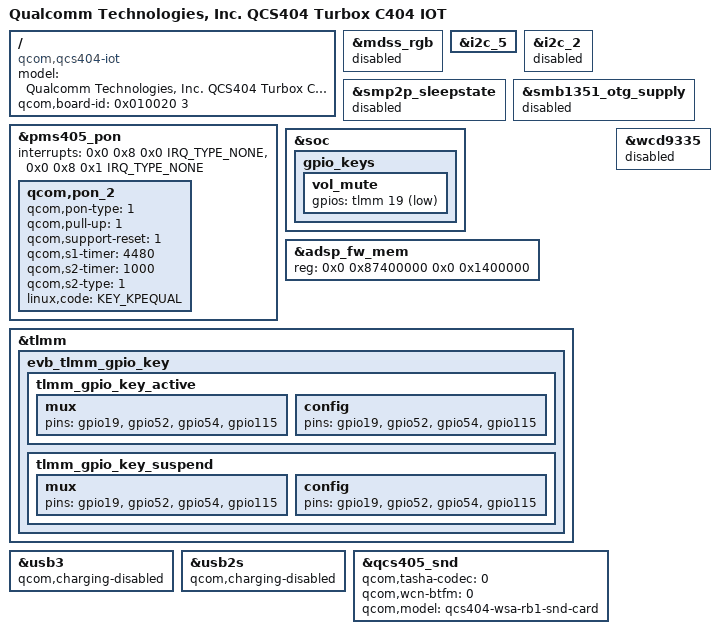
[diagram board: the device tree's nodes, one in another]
/*
 * Copyright (c) 2019-2020, The Linux Foundation. All rights reserved.
 *
 * This program is free software; you can redistribute it and/or modify
 * it under the terms of the GNU General Public License version 2 and
 * only version 2 as published by the Free Software Foundation.
 *
 * This program is distributed in the hope that it will be useful,
 * but WITHOUT ANY WARRANTY; without even the implied warranty of
 * MERCHANTABILITY or FITNESS FOR A PARTICULAR PURPOSE.  See the
 * GNU General Public License for more details.
 */

/dts-v1/;

#include "qcs404.dtsi"
#include "qcs405-wsa-audio-overlay.dtsi"

/ {
	model = "Qualcomm Technologies, Inc. QCS404 Turbox C404 IOT";
	compatible = "qcom,qcs404-iot", "qcom,qcs404", "qcom,iot";
	qcom,board-id = <0x010020 3>;
};

&mdss_rgb {
	status = "disabled";
};

&i2c_5 {
	status = "ok";
};

&i2c_2 {
	status = "disabled";
};

&smp2p_sleepstate {
	status = "disabled";
};

&smb1351_otg_supply {
	status = "disabled";
};

&pms405_pon {
	interrupts = <0x0 0x8 0x0 IRQ_TYPE_NONE>,
		     <0x0 0x8 0x1 IRQ_TYPE_NONE>;
	interrupt-names = "kpdpwr", "resin";
	qcom,pon_2 {
		qcom,pon-type = <1>;
		qcom,pull-up = <1>;
		qcom,support-reset = <1>;
		qcom,s1-timer = <4480>;
		qcom,s2-timer = <1000>;
		qcom,s2-type = <1>;
		linux,code = <KEY_KPEQUAL>;
	};
};

&soc {
	gpio_keys {
		vol_mute {
			gpios = <&tlmm 19 GPIO_ACTIVE_LOW>;
		};
	};
};

&adsp_fw_mem {
	reg = <0x0 0x87400000 0x0 0x1400000>;
};

&tlmm {
	evb_tlmm_gpio_key{
		tlmm_gpio_key_active: tlmm_gpio_key_active {
			mux {
				pins = "gpio19","gpio52","gpio54","gpio115";
			};

			config {
				pins = "gpio19","gpio52","gpio54","gpio115";
			};
		};

		tlmm_gpio_key_suspend: tlmm_gpio_key_suspend {
			mux {
				pins = "gpio19","gpio52","gpio54","gpio115";
			};

			config {
				pins = "gpio19","gpio52","gpio54","gpio115";
			};
		};
	};
};

&usb3 {
	qcom,charging-disabled;
	/delete-property/ extcon;
};

&usb2s {
	qcom,charging-disabled;
};

&qcs405_snd {
	qcom,tasha-codec = <0>;
	qcom,wcn-btfm = <0>;
	qcom,model = "qcs404-wsa-rb1-snd-card";
};

&wcd9335 {
	status = "disabled";
};
